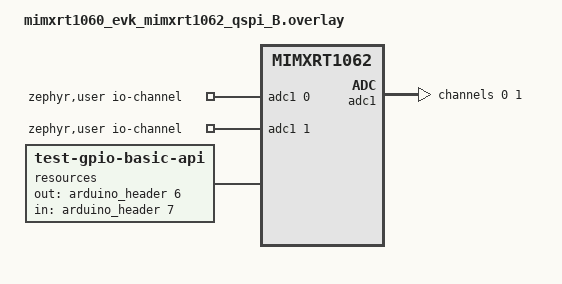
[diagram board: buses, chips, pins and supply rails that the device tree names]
/*
 * Copyright (c) 2022 Kumar Gala <galak@kernel.org>
 * Copyright (c) 2024 NXP
 *
 * SPDX-License-Identifier: Apache-2.0
 */

#include <zephyr/dt-bindings/memory-attr/memory-attr-arm.h>

&dtcm {
	zephyr,memory-attr = <DT_MEM_ARM(ATTR_MPU_RAM_NOCACHE)>;
};

tst_dma0: &edma0 {};

&itcm {
	zephyr,memory-attr = <DT_MEM_ARM(ATTR_MPU_RAM_NOCACHE)>;
};

#include <zephyr/dt-bindings/adc/mcux-lpadc.h>

/ {
	zephyr,user {
		io-channels = <&adc1 0>, <&adc1 1>;
	};
};

&adc1 {
	#address-cells = <1>;
	#size-cells = <0>;
	channel@0 {
		reg = <0>;
		zephyr,gain = "ADC_GAIN_1";
		zephyr,reference = "ADC_REF_INTERNAL";
		zephyr,acquisition-time = <ADC_ACQ_TIME_DEFAULT>;
		zephyr,resolution = <12>;
	};
	channel@1 {
		reg = <1>;
		zephyr,gain = "ADC_GAIN_1";
		zephyr,reference = "ADC_REF_INTERNAL";
		zephyr,acquisition-time = <ADC_ACQ_TIME_DEFAULT>;
		zephyr,resolution = <12>;
	};
};

/ {
	resources {
		compatible = "test-gpio-basic-api";
		status = "okay";
		out-gpios = <&arduino_header 6 (GPIO_ACTIVE_HIGH | GPIO_PUSH_PULL | GPIO_PULL_UP)>;
		in-gpios = <&arduino_header 7 (GPIO_ACTIVE_HIGH | GPIO_PUSH_PULL | GPIO_PULL_UP)>;
	};
};
